AUTOSAR XML (schema 3.1.2)
package /Components/SWC_AirEfcEngCylPrmT
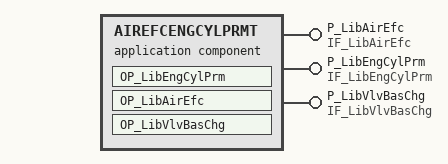
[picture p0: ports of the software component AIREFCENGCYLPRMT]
  application software component type AIREFCENGCYLPRMT  # AirEfcEngCylPrmT
    provide port P_LibAirEfc: server-com-spec{operation=OP_LibAirEfc, queue-length=1}, provided-interface=IF_LibAirEfc
    provide port P_LibEngCylPrm: server-com-spec{operation=OP_LibEngCylPrm, queue-length=1}, provided-interface=IF_LibEngCylPrm
    provide port P_LibVlvBasChg: server-com-spec{operation=OP_LibVlvBasChg, queue-length=1}, provided-interface=IF_LibVlvBasChg
  internal behavior IB_AirEfcEngCylPrmT: component=AIREFCENGCYLPRMT
    operation invoked event EV_LibVlvBasChg: start-on-event=OP_LibVlvBasChg, operation=P_LibVlvBasChg.OP_LibVlvBasChg
    operation invoked event EV_LibEngCylPrm: start-on-event=OP_LibEngCylPrm, operation=P_LibEngCylPrm.OP_LibEngCylPrm
    operation invoked event EV_LibAirEfc: start-on-event=OP_LibAirEfc, operation=P_LibAirEfc.OP_LibAirEfc
    runnable OP_LibEngCylPrm: can-be-invoked-concurrently=true
    runnable OP_LibAirEfc: can-be-invoked-concurrently=true
    runnable OP_LibVlvBasChg
  swc implementation Imp_AirEfcEngCylPrmT: code-generator=Real-Time Workshop Embedded Coder 5.5 (R2010a) 25-Jan-2010, programming-language=C, behavior=IB_AirEfcEngCylPrmT
    code-descriptors:
      code CodeDescriptor: type=SRC
